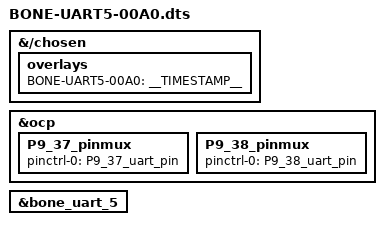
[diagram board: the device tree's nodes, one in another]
/*
 * Copyright (C) 2020 Deepak Khatri <deepaklorkhatri7@gmail.com>
 *
 * Virtual cape for /dev/bone/uart/5
 *
 * This program is free software; you can redistribute it and/or modify
 * it under the terms of the GNU General Public License version 2 as
 * published by the Free Software Foundation.
 */
 
/dts-v1/;
/plugin/;

/*
* Helper to show loaded overlays under: /proc/device-tree/chosen/overlays/
*/
&{/chosen} {
    overlays {
        BONE-UART5-00A0 = __TIMESTAMP__;
    };
};

/*
* Update the default pinmux of the pins.
*/
&ocp {
    P9_37_pinmux { pinctrl-0 = <&P9_37_uart_pin>; };    /* UART TX*/
    P9_38_pinmux { pinctrl-0 = <&P9_38_uart_pin>; };    /* UART RX*/
};

&bone_uart_5 {
    // See these files for the definition
    // https://github.com/beagleboard/BeagleBoard-DeviceTrees/src/arm/bbai-bone-buses.dtsi
    // https://github.com/beagleboard/BeagleBoard-DeviceTrees/src/arm/bbb-bone-buses.dtsi
    status = "okay";
};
